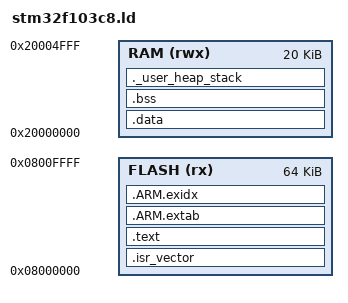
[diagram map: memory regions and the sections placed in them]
ENTRY(Reset_Handler)

MEMORY
{
  FLASH (rx)  : ORIGIN = 0x08000000, LENGTH = 64K
  RAM   (rwx) : ORIGIN = 0x20000000, LENGTH = 20K
}

_estack = ORIGIN(RAM) + LENGTH(RAM);

SECTIONS
{
  .isr_vector :
  {
    KEEP(*(.isr_vector))
  } > FLASH

  .text :
  {
    *(.text*)
    *(.rodata*)
    KEEP(*(.init))
    KEEP(*(.fini))
  } > FLASH

  .ARM.extab :
  {
    *(.ARM.extab* .gnu.linkonce.armextab.*)
  } > FLASH

  .ARM.exidx :
  {
    __exidx_start = .;
    *(.ARM.exidx* .gnu.linkonce.armexidx.*)
    __exidx_end = .;
    . = ALIGN(4);
    _etext = .;
  } > FLASH

  _sidata = LOADADDR(.data);

  .data : AT (_etext)
  {
    . = ALIGN(4);
    _sdata = .;
    *(.data*)
    . = ALIGN(4);
    _edata = .;
  } > RAM

  .bss :
  {
    . = ALIGN(4);
    _sbss = .;
    *(.bss*)
    *(COMMON)
    . = ALIGN(4);
    _ebss = .;
  } > RAM

  ._user_heap_stack :
  {
    . = ALIGN(8);
    PROVIDE(end = .);
    PROVIDE(_end = .);
    . = . + 0x400;
    . = . + 0x400;
    . = ALIGN(8);
  } > RAM
}
